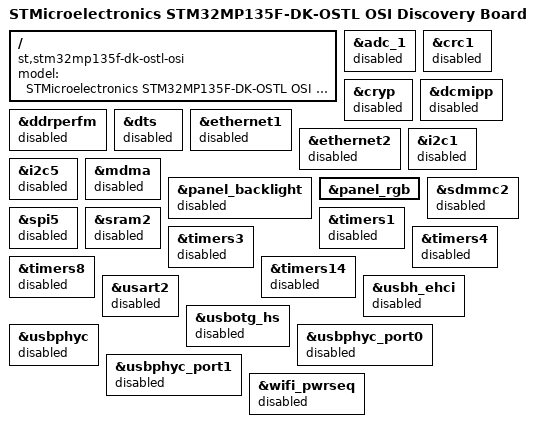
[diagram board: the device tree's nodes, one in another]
// SPDX-License-Identifier: (GPL-2.0-only OR BSD-3-Clause)
/*
 * Copyright (C) STMicroelectronics 2025 - All Rights Reserved
 * Author: Alexandre Torgue <alexandre.torgue@foss.st.com> for STMicroelectronics.
 */

/dts-v1/;

#include "stm32mp135f-dk-ostl.dts"

/ {
	model = "STMicroelectronics STM32MP135F-DK-OSTL OSI Discovery Board";
	compatible = "st,stm32mp135f-dk-ostl-osi", "st,stm32mp135f-dk-ostl", "st,stm32mp135f-dk", "st,stm32mp135";
};

&adc_1 {
	status = "disabled";
};

&crc1 {
	status = "disabled";
};

&cryp {
	status = "disabled";
};

&dcmipp {
	status = "disabled";
};

&ddrperfm {
	status = "disabled";
};

&dts {
	status = "disabled";
};

&ethernet1 {
	status = "disabled";
};

&ethernet2 {
	status = "disabled";
};

&i2c1 {
	status = "disabled";
};

&i2c5 {
	status = "disabled";
};

&mdma {
	status = "disabled";
};

&panel_backlight {
	status = "disabled";
};

&panel_rgb {
	/delete-property/ backlight;
};

&sdmmc2 {
	status = "disabled";
};

&spi5 {
	status = "disabled";
};

&sram2 {
	status = "disabled";
};

&timers1 {
	status = "disabled";
};

&timers3 {
	status = "disabled";
};

&timers4 {
	status = "disabled";
};

&timers8 {
	status = "disabled";
};

&timers14 {
	status = "disabled";
};

&usart2 {
	status = "disabled";
};

&usbh_ehci {
	status = "disabled";
};

&usbotg_hs {
	status = "disabled";
};

&usbphyc {
	status = "disabled";
};

&usbphyc_port0 {
	status = "disabled";
};

&usbphyc_port1 {
	status = "disabled";
};

&wifi_pwrseq {
	status = "disabled";
};
